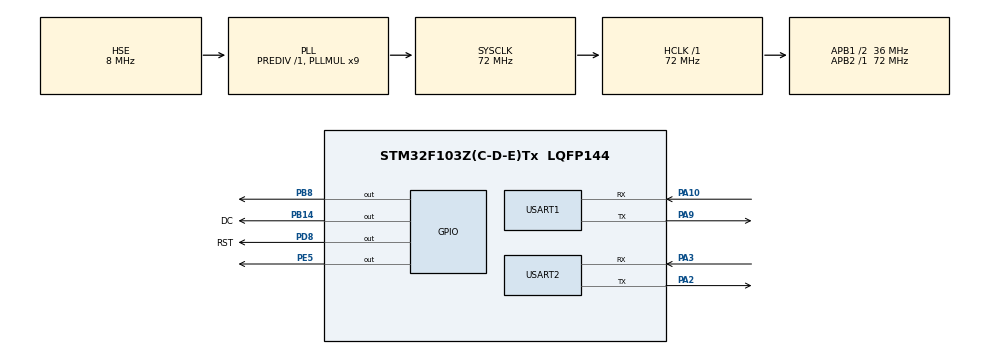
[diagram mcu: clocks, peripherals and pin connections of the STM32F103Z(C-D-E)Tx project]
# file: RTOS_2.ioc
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Dma.Request0=USART1_TX
Dma.Request1=USART1_RX
Dma.Request2=USART2_TX
Dma.USART1_RX.1.Direction=DMA_PERIPH_TO_MEMORY
Dma.USART1_RX.1.Instance=DMA1_Channel5
Dma.USART1_RX.1.MemDataAlignment=DMA_MDATAALIGN_BYTE
Dma.USART1_RX.1.MemInc=DMA_MINC_ENABLE
Dma.USART1_RX.1.Mode=DMA_CIRCULAR
Dma.USART1_RX.1.PeriphDataAlignment=DMA_PDATAALIGN_BYTE
Dma.USART1_RX.1.PeriphInc=DMA_PINC_DISABLE
Dma.USART1_RX.1.Priority=DMA_PRIORITY_LOW
Dma.USART1_TX.0.Direction=DMA_MEMORY_TO_PERIPH
Dma.USART1_TX.0.Instance=DMA1_Channel4
Dma.USART1_TX.0.MemDataAlignment=DMA_MDATAALIGN_BYTE
Dma.USART1_TX.0.MemInc=DMA_MINC_ENABLE
Dma.USART1_TX.0.Mode=DMA_NORMAL
Dma.USART1_TX.0.PeriphDataAlignment=DMA_PDATAALIGN_BYTE
Dma.USART1_TX.0.PeriphInc=DMA_PINC_DISABLE
Dma.USART1_TX.0.Priority=DMA_PRIORITY_LOW
Dma.USART2_TX.2.Direction=DMA_MEMORY_TO_PERIPH
Dma.USART2_TX.2.Instance=DMA1_Channel7
Dma.USART2_TX.2.MemDataAlignment=DMA_MDATAALIGN_BYTE
Dma.USART2_TX.2.MemInc=DMA_MINC_ENABLE
Dma.USART2_TX.2.Mode=DMA_NORMAL
Dma.USART2_TX.2.PeriphDataAlignment=DMA_PDATAALIGN_BYTE
Dma.USART2_TX.2.PeriphInc=DMA_PINC_DISABLE
Dma.USART2_TX.2.Priority=DMA_PRIORITY_LOW
FREERTOS.Tasks01=defaultTask,0,128,StartDefaultTask,Default,NULL,Dynamic,NULL,NULL
Mcu.Family=STM32F1
Mcu.Name=STM32F103Z(C-D-E)Tx
Mcu.Package=LQFP144
NVIC.DMA1_Channel4_IRQn=true\:5\:0\:false\:false\:true\:true\:false\:true\:true
NVIC.DMA1_Channel5_IRQn=true\:5\:0\:false\:false\:true\:true\:false\:true\:true
NVIC.DMA1_Channel7_IRQn=true\:5\:0\:false\:false\:true\:true\:false\:true\:true
NVIC.PriorityGroup=NVIC_PRIORITYGROUP_4
NVIC.TIM8_UP_IRQn=true\:15\:0\:false\:false\:true\:false\:false\:true\:true
NVIC.TimeBase=TIM8_UP_IRQn
NVIC.TimeBaseIP=TIM8
NVIC.USART1_IRQn=true\:5\:0\:false\:false\:true\:true\:true\:true\:true
NVIC.USART2_IRQn=true\:5\:0\:false\:false\:true\:true\:true\:true\:true
OSC_IN.Mode=HSE-External-Oscillator
OSC_IN.Signal=RCC_OSC_IN
OSC_OUT.Mode=HSE-External-Oscillator
OSC_OUT.Signal=RCC_OSC_OUT
PA10.Mode=Asynchronous
PA10.Signal=USART1_RX
PA13.Mode=Serial_Wire
PA13.Signal=SYS_JTMS-SWDIO
PA14.Mode=Serial_Wire
PA14.Signal=SYS_JTCK-SWCLK
PA2.Mode=Asynchronous
PA2.Signal=USART2_TX
PA3.Mode=Asynchronous
PA3.Signal=USART2_RX
PA9.Mode=Asynchronous
PA9.Signal=USART1_TX
PB12.GPIO_Label=CS
PB12.Signal=SPI2_NSS
PB13.GPIO_Label=SCL
PB13.Signal=SPI2_SCK
PB14.GPIO_Label=DC
PB14.Signal=GPIO_Output
PB15.GPIO_Label=SDA
PB15.Signal=SPI2_MOSI
PB8.Signal=GPIO_Output
PC14-OSC32_IN.Mode=LSE-External-Oscillator
PC14-OSC32_IN.Signal=RCC_OSC32_IN
PC15-OSC32_OUT.Mode=LSE-External-Oscillator
PC15-OSC32_OUT.Signal=RCC_OSC32_OUT
PD8.GPIO_Label=RST
PD8.Signal=GPIO_Output
PE5.Signal=GPIO_Output
ProjectManager.HeapSize=0x200
ProjectManager.StackSize=0x800
ProjectManager.TargetToolchain=MDK-ARM V5.32
RCC.AHBFreq_Value=72000000
RCC.APB1CLKDivider=RCC_HCLK_DIV2
RCC.APB1Freq_Value=36000000
RCC.APB1TimFreq_Value=72000000
RCC.APB2Freq_Value=72000000
RCC.APB2TimFreq_Value=72000000
RCC.HCLKFreq_Value=72000000
RCC.PLLMUL=RCC_PLL_MUL9
RCC.PLLSourceVirtual=RCC_PLLSOURCE_HSE
RCC.SYSCLKFreq_VALUE=72000000
RCC.SYSCLKSource=RCC_SYSCLKSOURCE_PLLCLK
RCC.USBFreq_Value=72000000
USART1.VirtualMode=VM_ASYNC
USART2.VirtualMode=VM_ASYNC
VP_FREERTOS_VS_CMSIS_V1.Mode=CMSIS_V1
VP_SYS_VS_tim8.Mode=TIM8
board=custom

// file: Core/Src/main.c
/* USER CODE BEGIN Header */
/**
  ******************************************************************************
  * @file           : main.c
  * @brief          : Main program body
  ******************************************************************************
  * @attention
  *
  * Copyright (c) 2023 STMicroelectronics.
  * All rights reserved.
  *
  * This software is licensed under terms that can be found in the LICENSE file
  * in the root directory of this software component.
  * If no LICENSE file comes with this software, it is provided AS-IS.
  *
  ******************************************************************************
  */
/* USER CODE END Header */
#include "main.h"
#include "cmsis_os.h"
#include "dma.h"
#include "usart.h"
#include "gpio.h"

void SystemClock_Config(void);
void MX_FREERTOS_Init(void);

int main(void)
{

  /* MCU Configuration--------------------------------------------------------*/

  /* Reset of all peripherals, Initializes the Flash interface and the Systick. */
  HAL_Init();

  /* Configure the system clock */
  SystemClock_Config();

  /* Initialize all configured peripherals */
  MX_GPIO_Init();
  MX_DMA_Init();
  MX_USART1_UART_Init();
  MX_USART2_UART_Init();

  /* Call init function for freertos objects (in freertos.c) */
  MX_FREERTOS_Init();

  /* Start scheduler */
  osKernelStart();

  /* We should never get here as control is now taken by the scheduler */
  /* Infinite loop */
  while (1)
  {

  }
}

void SystemClock_Config(void)
{
  RCC_OscInitTypeDef RCC_OscInitStruct = {0};
  RCC_ClkInitTypeDef RCC_ClkInitStruct = {0};

  /** Initializes the RCC Oscillators according to the specified parameters
  * in the RCC_OscInitTypeDef structure.
  */
  RCC_OscInitStruct.OscillatorType = RCC_OSCILLATORTYPE_HSE;
  RCC_OscInitStruct.HSEState = RCC_HSE_ON;
  RCC_OscInitStruct.HSEPredivValue = RCC_HSE_PREDIV_DIV1;
  RCC_OscInitStruct.HSIState = RCC_HSI_ON;
  RCC_OscInitStruct.PLL.PLLState = RCC_PLL_ON;
  RCC_OscInitStruct.PLL.PLLSource = RCC_PLLSOURCE_HSE;
  RCC_OscInitStruct.PLL.PLLMUL = RCC_PLL_MUL9;
  if (HAL_RCC_OscConfig(&RCC_OscInitStruct) != HAL_OK)
  {
    Error_Handler();
  }

  /** Initializes the CPU, AHB and APB buses clocks
  */
  RCC_ClkInitStruct.ClockType = RCC_CLOCKTYPE_HCLK|RCC_CLOCKTYPE_SYSCLK
                              |RCC_CLOCKTYPE_PCLK1|RCC_CLOCKTYPE_PCLK2;
  RCC_ClkInitStruct.SYSCLKSource = RCC_SYSCLKSOURCE_PLLCLK;
  RCC_ClkInitStruct.AHBCLKDivider = RCC_SYSCLK_DIV1;
  RCC_ClkInitStruct.APB1CLKDivider = RCC_HCLK_DIV2;
  RCC_ClkInitStruct.APB2CLKDivider = RCC_HCLK_DIV1;

  if (HAL_RCC_ClockConfig(&RCC_ClkInitStruct, FLASH_LATENCY_2) != HAL_OK)
  {
    Error_Handler();
  }
}

void HAL_TIM_PeriodElapsedCallback(TIM_HandleTypeDef *htim)
{
  if (htim->Instance == TIM8) {
    HAL_IncTick();
  }
}

void Error_Handler(void)
{
  __disable_irq();
  while (1)
  {
  }
}

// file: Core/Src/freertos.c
/* USER CODE BEGIN Header */
/**
  ******************************************************************************
  * File Name          : freertos.c
  * Description        : Code for freertos applications
  ******************************************************************************
  * @attention
  *
  * Copyright (c) 2023 STMicroelectronics.
  * All rights reserved.
  *
  * This software is licensed under terms that can be found in the LICENSE file
  * in the root directory of this software component.
  * If no LICENSE file comes with this software, it is provided AS-IS.
  *
  ******************************************************************************
  */
/* USER CODE END Header */

#include "FreeRTOS.h"
#include "task.h"
#include "main.h"
#include "cmsis_os.h"

/* USER CODE BEGIN Includes */
#include "usart.h"
#include "string.h"
/* USER CODE END Includes */

osThreadId defaultTaskHandle;

/* USER CODE BEGIN FunctionPrototypes */
osThreadId TFTLCDTaskHandle;
void StartTFTLCDTask(void const * argument);
/* USER CODE END FunctionPrototypes */

void StartDefaultTask(void const * argument);

void MX_FREERTOS_Init(void); /* (MISRA C 2004 rule 8.1) */

/* GetIdleTaskMemory prototype (linked to static allocation support) */
void vApplicationGetIdleTaskMemory( StaticTask_t **ppxIdleTaskTCBBuffer, StackType_t **ppxIdleTaskStackBuffer, uint32_t *pulIdleTaskStackSize );

/* USER CODE BEGIN GET_IDLE_TASK_MEMORY */
static StaticTask_t xIdleTaskTCBBuffer;
static StackType_t xIdleStack[configMINIMAL_STACK_SIZE];

void vApplicationGetIdleTaskMemory( StaticTask_t **ppxIdleTaskTCBBuffer, StackType_t **ppxIdleTaskStackBuffer, uint32_t *pulIdleTaskStackSize )
{
  *ppxIdleTaskTCBBuffer = &xIdleTaskTCBBuffer;
  *ppxIdleTaskStackBuffer = &xIdleStack[0];
  *pulIdleTaskStackSize = configMINIMAL_STACK_SIZE;
  /* place for user code */
}
/* USER CODE END GET_IDLE_TASK_MEMORY */

void MX_FREERTOS_Init(void) {

  /* Create the thread(s) */
  /* definition and creation of defaultTask */
  osThreadDef(defaultTask, StartDefaultTask, osPriorityNormal, 0, 128);
  defaultTaskHandle = osThreadCreate(osThread(defaultTask), NULL);

}

void StartDefaultTask(void const * argument)
{
  /* USER CODE BEGIN StartDefaultTask */
  /* Infinite loop */
  for(;;)
  {
    osDelay(1);

		osThreadDef(TFTLCDTask, StartTFTLCDTask, osPriorityNormal, 0, 128);
		TFTLCDTaskHandle = osThreadCreate(osThread(TFTLCDTask), NULL);

		vTaskDelete(defaultTaskHandle);
  }
  /* USER CODE END StartDefaultTask */
}

/* USER CODE BEGIN Application */

void StartTFTLCDTask(void const * argument)
{
	for(;;)
	{
		osDelay(10);
		if(usart1_rx_flag == 1)
		{
			cjson_parse_fail_flag = cJSON_msg_parse((char*)receive_data);
			usart1_rx_flag  = 0;
			memset(receive_data,0,UART1_Rx_Buffer_Max_Num);//ˢ��receive������

		}

	}
}
/* USER CODE END Application */
